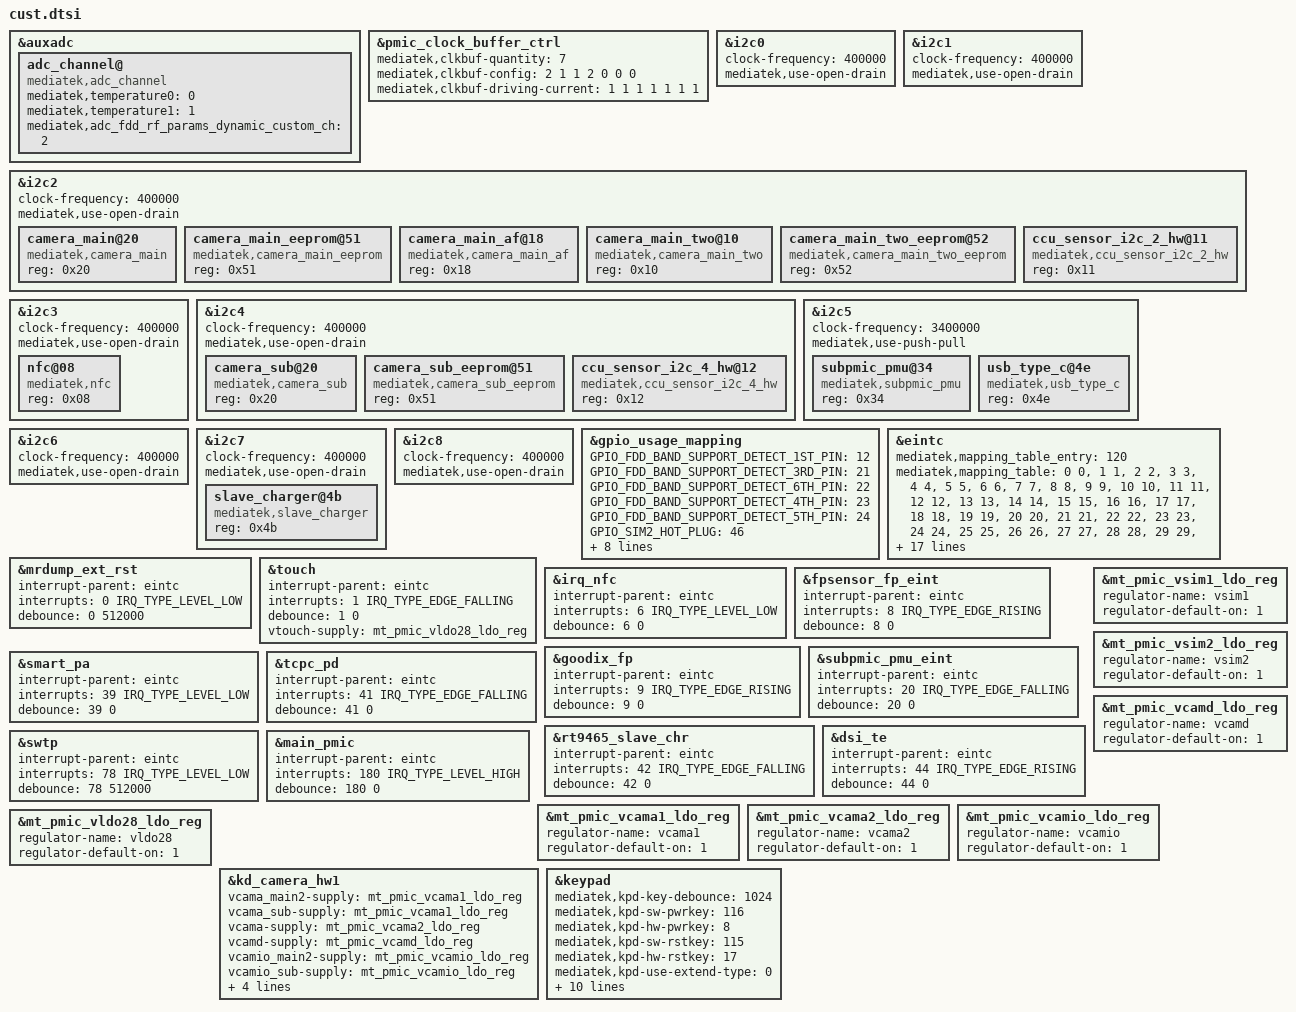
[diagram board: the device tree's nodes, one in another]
/*
 * Generated by MTK SP DrvGen Version: 3.5.160809 for MT6768.
 * 2024-12-11 20:51:26
 * Do Not Modify The File.
 * Copyright Mediatek Inc. (c) 2016.
*/

/*************************
 * ADC DTSI File
*************************/

&auxadc {
	adc_channel@ {
		compatible = "mediatek,adc_channel";
		mediatek,temperature0 = <0>;
		mediatek,temperature1 = <1>;
		mediatek,adc_fdd_rf_params_dynamic_custom_ch = <2>;
		status = "okay";
	};
};


/*************************
 * CLK_BUF DTSI File
*************************/

&pmic_clock_buffer_ctrl {
	mediatek,clkbuf-quantity = <7>;
	mediatek,clkbuf-config = <2 1 1 2 0 0 0>;
	mediatek,clkbuf-driving-current = <1 1 1 1 1 1 1>;
	status = "okay";
};


/*************************
 * I2C DTSI File
*************************/

&i2c0 {
	#address-cells = <1>;
	#size-cells = <0>;
	clock-frequency = <400000>;
	mediatek,use-open-drain;
};

&i2c1 {
	#address-cells = <1>;
	#size-cells = <0>;
	clock-frequency = <400000>;
	mediatek,use-open-drain;
};

&i2c2 {
	#address-cells = <1>;
	#size-cells = <0>;
	clock-frequency = <400000>;
	mediatek,use-open-drain;
	camera_main@20 {
		compatible = "mediatek,camera_main";
		reg = <0x20>;
		status = "okay";
	};

	camera_main_eeprom@51 {
		compatible = "mediatek,camera_main_eeprom";
		reg = <0x51>;
		status = "okay";
	};

	camera_main_af@18 {
		compatible = "mediatek,camera_main_af";
		reg = <0x18>;
		status = "okay";
	};

	camera_main_two@10 {
		compatible = "mediatek,camera_main_two";
		reg = <0x10>;
		status = "okay";
	};

	camera_main_two_eeprom@52 {
		compatible = "mediatek,camera_main_two_eeprom";
		reg = <0x52>;
		status = "okay";
	};

	ccu_sensor_i2c_2_hw@11 {
		compatible = "mediatek,ccu_sensor_i2c_2_hw";
		reg = <0x11>;
		status = "okay";
	};

};

&i2c3 {
	#address-cells = <1>;
	#size-cells = <0>;
	clock-frequency = <400000>;
	mediatek,use-open-drain;
	nfc@08 {
		compatible = "mediatek,nfc";
		reg = <0x08>;
		status = "okay";
	};

};

&i2c4 {
	#address-cells = <1>;
	#size-cells = <0>;
	clock-frequency = <400000>;
	mediatek,use-open-drain;
	camera_sub@20 {
		compatible = "mediatek,camera_sub";
		reg = <0x20>;
		status = "okay";
	};

	camera_sub_eeprom@51 {
		compatible = "mediatek,camera_sub_eeprom";
		reg = <0x51>;
		status = "okay";
	};

	ccu_sensor_i2c_4_hw@12 {
		compatible = "mediatek,ccu_sensor_i2c_4_hw";
		reg = <0x12>;
		status = "okay";
	};

};

&i2c5 {
	#address-cells = <1>;
	#size-cells = <0>;
	clock-frequency = <3400000>;
	mediatek,use-push-pull;
	subpmic_pmu@34 {
		compatible = "mediatek,subpmic_pmu";
		reg = <0x34>;
		status = "okay";
	};

	usb_type_c@4e {
		compatible = "mediatek,usb_type_c";
		reg = <0x4e>;
		status = "okay";
	};

};

&i2c6 {
	#address-cells = <1>;
	#size-cells = <0>;
	clock-frequency = <400000>;
	mediatek,use-open-drain;
};

&i2c7 {
	#address-cells = <1>;
	#size-cells = <0>;
	clock-frequency = <400000>;
	mediatek,use-open-drain;
	slave_charger@4b {
		compatible = "mediatek,slave_charger";
		reg = <0x4b>;
		status = "okay";
	};

};

&i2c8 {
	#address-cells = <1>;
	#size-cells = <0>;
	clock-frequency = <400000>;
	mediatek,use-open-drain;
};



/*************************
 * GPIO DTSI File
*************************/

&gpio_usage_mapping {
	GPIO_FDD_BAND_SUPPORT_DETECT_1ST_PIN = <12>;
	GPIO_FDD_BAND_SUPPORT_DETECT_3RD_PIN = <21>;
	GPIO_FDD_BAND_SUPPORT_DETECT_6TH_PIN = <22>;
	GPIO_FDD_BAND_SUPPORT_DETECT_4TH_PIN = <23>;
	GPIO_FDD_BAND_SUPPORT_DETECT_5TH_PIN = <24>;
	GPIO_SIM2_HOT_PLUG = <46>;
	GPIO_SIM1_HOT_PLUG = <47>;
	GPIO_SIM2_SIO = <155>;
	GPIO_SIM2_SRST = <156>;
	GPIO_SIM2_SCLK = <157>;
	GPIO_FDD_BAND_SUPPORT_DETECT_2ND_PIN = <158>;
	GPIO_SIM1_SCLK = <172>;
	GPIO_SIM1_SRST = <173>;
	GPIO_SIM1_SIO = <174>;
};


/*************************
 * EINT DTSI File
*************************/

#include <dt-bindings/interrupt-controller/irq.h>
#include <dt-bindings/interrupt-controller/arm-gic.h>

&eintc {
	mediatek,mapping_table_entry = <120>;
			/* <gpio_pin, eint_pin> */
	mediatek,mapping_table = <0 0>,
					<1 1>,
					<2 2>,
					<3 3>,
					<4 4>,
					<5 5>,
					<6 6>,
					<7 7>,
					<8 8>,
					<9 9>,
					<10 10>,
					<11 11>,
					<12 12>,
					<13 13>,
					<14 14>,
					<15 15>,
					<16 16>,
					<17 17>,
					<18 18>,
					<19 19>,
					<20 20>,
					<21 21>,
					<22 22>,
					<23 23>,
					<24 24>,
					<25 25>,
					<26 26>,
					<27 27>,
					<28 28>,
					<29 29>,
					<30 30>,
					<31 31>,
					<32 32>,
					<33 33>,
					<34 34>,
					<35 35>,
					<36 36>,
					<37 37>,
					<38 38>,
					<39 39>,
					<40 40>,
					<41 41>,
					<42 42>,
					<43 43>,
					<44 44>,
					<45 45>,
					<46 46>,
					<47 47>,
					<48 48>,
					<49 49>,
					<50 50>,
					<51 51>,
					<52 52>,
					<53 53>,
					<54 54>,
					<55 55>,
					<56 56>,
					<57 57>,
					<58 58>,
					<59 59>,
					<60 60>,
					<61 61>,
					<62 62>,
					<63 63>,
					<64 64>,
					<65 65>,
					<66 66>,
					<67 67>,
					<68 68>,
					<69 69>,
					<70 70>,
					<71 71>,
					<72 72>,
					<73 73>,
					<74 74>,
					<75 75>,
					<76 76>,
					<77 77>,
					<78 78>,
					<79 79>,
					<80 80>,
					<81 81>,
					<82 82>,
					<83 83>,
					<84 84>,
					<85 85>,
					<86 86>,
					<87 87>,
					<88 88>,
					<89 89>,
					<90 90>,
					<91 91>,
					<92 92>,
					<93 93>,
					<94 94>,
					<95 95>,
					<96 96>,
					<97 97>,
					<98 98>,
					<99 99>,
					<100 100>,
					<101 101>,
					<102 102>,
					<103 103>,
					<104 104>,
					<105 105>,
					<106 106>,
					<107 107>,
					<108 108>,
					<109 109>,
					<110 110>,
					<111 111>,
					<112 112>,
					<180 144>,
					<181 145>,
					<182 147>,
					<183 148>,
					<184 149>,
					<185 150>,
					<186 151>;
	mediatek,builtin_entry = <0>;
};

&mrdump_ext_rst {
	interrupt-parent = <&eintc>;
	interrupts = <0 IRQ_TYPE_LEVEL_LOW>;
	debounce = <0 512000>;
	status = "okay";
};

&touch {
	interrupt-parent = <&eintc>;
	interrupts = <1 IRQ_TYPE_EDGE_FALLING>;
	debounce = <1 0>;
	status = "okay";
};

&irq_nfc {
	interrupt-parent = <&eintc>;
	interrupts = <6 IRQ_TYPE_LEVEL_LOW>;
	debounce = <6 0>;
	status = "okay";
};

&fpsensor_fp_eint {
	interrupt-parent = <&eintc>;
	interrupts = <8 IRQ_TYPE_EDGE_RISING>;
	debounce = <8 0>;
	status = "okay";
};

&goodix_fp {
	interrupt-parent = <&eintc>;
	interrupts = <9 IRQ_TYPE_EDGE_RISING>;
	debounce = <9 0>;
	status = "okay";
};

&subpmic_pmu_eint {
	interrupt-parent = <&eintc>;
	interrupts = <20 IRQ_TYPE_EDGE_FALLING>;
	debounce = <20 0>;
	status = "okay";
};

&smart_pa {
	interrupt-parent = <&eintc>;
	interrupts = <39 IRQ_TYPE_LEVEL_LOW>;
	debounce = <39 0>;
	status = "okay";
};

&tcpc_pd {
	interrupt-parent = <&eintc>;
	interrupts = <41 IRQ_TYPE_EDGE_FALLING>;
	debounce = <41 0>;
	status = "okay";
};

&rt9465_slave_chr {
	interrupt-parent = <&eintc>;
	interrupts = <42 IRQ_TYPE_EDGE_FALLING>;
	debounce = <42 0>;
	status = "okay";
};

&dsi_te {
	interrupt-parent = <&eintc>;
	interrupts = <44 IRQ_TYPE_EDGE_RISING>;
	debounce = <44 0>;
	status = "okay";
};

&swtp {
	interrupt-parent = <&eintc>;
	interrupts = <78 IRQ_TYPE_LEVEL_LOW>;
	debounce = <78 512000>;
	status = "okay";
};

&main_pmic {
	interrupt-parent = <&eintc>;
	interrupts = <180 IRQ_TYPE_LEVEL_HIGH>;
	debounce = <180 0>;
	status = "okay";
};



/*************************
 * MD1_EINT DTSI File
*************************/

&eintc {
};


/*************************
 * PMIC DTSI File
*************************/

&mt_pmic_vcama1_ldo_reg {
	regulator-name = "vcama1";
	regulator-default-on = <1>; /* 0:skip, 1: off, 2:on */
	status = "okay";
};
&mt_pmic_vcama2_ldo_reg {
	regulator-name = "vcama2";
	regulator-default-on = <1>; /* 0:skip, 1: off, 2:on */
	status = "okay";
};
&mt_pmic_vsim1_ldo_reg {
	regulator-name = "vsim1";
	regulator-default-on = <1>; /* 0:skip, 1: off, 2:on */
	status = "okay";
};
&mt_pmic_vsim2_ldo_reg {
	regulator-name = "vsim2";
	regulator-default-on = <1>; /* 0:skip, 1: off, 2:on */
	status = "okay";
};
&mt_pmic_vcamd_ldo_reg {
	regulator-name = "vcamd";
	regulator-default-on = <1>; /* 0:skip, 1: off, 2:on */
	status = "okay";
};
&mt_pmic_vcamio_ldo_reg {
	regulator-name = "vcamio";
	regulator-default-on = <1>; /* 0:skip, 1: off, 2:on */
	status = "okay";
};
&mt_pmic_vldo28_ldo_reg {
	regulator-name = "vldo28";
	regulator-default-on = <1>; /* 0:skip, 1: off, 2:on */
	status = "okay";
};

&kd_camera_hw1 {
	vcama_main2-supply = <&mt_pmic_vcama1_ldo_reg>;
	vcama_sub-supply = <&mt_pmic_vcama1_ldo_reg>;
	vcama-supply = <&mt_pmic_vcama2_ldo_reg>;
	vcamd-supply = <&mt_pmic_vcamd_ldo_reg>;
	vcamio_main2-supply = <&mt_pmic_vcamio_ldo_reg>;
	vcamio_sub-supply = <&mt_pmic_vcamio_ldo_reg>;
	vcamio-supply = <&mt_pmic_vcamio_ldo_reg>;
	vcamaf_main2-supply = <&mt_pmic_vldo28_ldo_reg>;
	vcamaf_sub-supply = <&mt_pmic_vldo28_ldo_reg>;
	vcamaf-supply = <&mt_pmic_vldo28_ldo_reg>;
	status = "okay";
};

&touch {
	vtouch-supply = <&mt_pmic_vldo28_ldo_reg>;
	status = "okay";
};


/*************************
 * POWER DTSI File
*************************/



/*************************
 * KPD DTSI File
*************************/

&keypad {
	mediatek,kpd-key-debounce = <1024>;
	mediatek,kpd-sw-pwrkey = <116>;
	mediatek,kpd-hw-pwrkey = <8>;
	mediatek,kpd-sw-rstkey  = <115>;
	mediatek,kpd-hw-rstkey = <17>;
	mediatek,kpd-use-extend-type = <0>;
	/*HW Keycode [0~71] -> Linux Keycode*/
	mediatek,kpd-hw-map-num = <72>;
	mediatek,kpd-hw-init-map = <114 0 0 0 0 0 0 0 0 0 0 0 0 0 0 0 0 0 0 0 0 0 0 0 0 0 0 0 0 0 0 0 0 0 0 0 0 0 0 0 0 0 0 0 0 0 0 0 0 0 0 0 0 0 0 0 0 0 0 0 0 0 0 0 0 0 0 0 0 0 0 0 >;
	mediatek,kpd-pwrkey-eint-gpio = <0>;
	mediatek,kpd-pwkey-gpio-din  = <0>;
	mediatek,kpd-hw-dl-key0 = <17>;
	mediatek,kpd-hw-dl-key1 = <0>;
	mediatek,kpd-hw-dl-key2 = <8>;
	mediatek,kpd-hw-recovery-key = <17>;
	mediatek,kpd-hw-factory-key = <0>;
	status = "okay";
};


